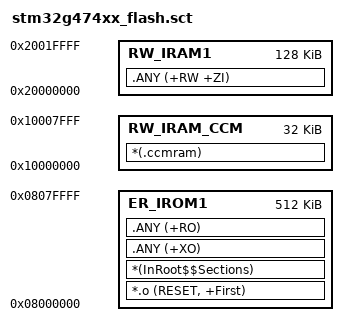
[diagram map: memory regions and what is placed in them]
; *********************************************************************************
; *** Scatter-Loading Description File generated by STM32CubeMX/LinkerGenerator ***
; *********************************************************************************;

LR_IROM1 0x8000000 0x00080000  {  ; load_region size_region
  ER_IROM1 0x8000000 0x00080000  {  ; load address = execution address
   *.o (RESET, +First)
   *(InRoot$$Sections)
   .ANY (+XO)
   .ANY (+RO)
  }
  RW_IRAM1 0x20000000 0x00020000  {  ; RW/ZI data in main SRAM (128KB)
   .ANY (+RW +ZI)
  }
  ; CCM-SRAM execution region for time-critical code (32KB at 0x10000000)
  ; Code is stored in Flash but executed from CCM-SRAM (copied at startup)
  ; Functions marked with CCMRAM_FUNCTION attribute are placed here
  RW_IRAM_CCM 0x10000000 0x00008000  {
   *(.ccmram)
  }
;***region***;
;***endregion***;
}


/*-Start of  regions- Auto-generated By STM32CubeMX-*/
